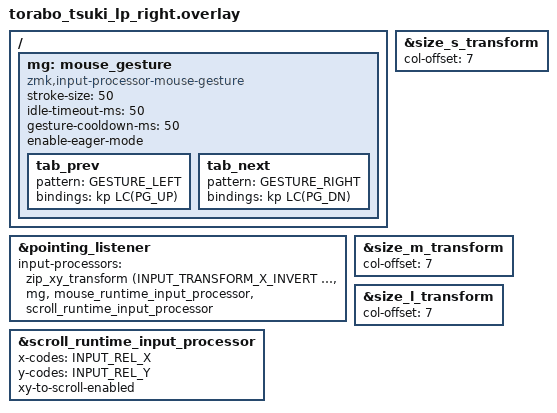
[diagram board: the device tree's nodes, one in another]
#include "torabo_tsuki_lp.dtsi"
#include <input/processors.dtsi>
#include <dt-bindings/zmk/input_transform.h>
#include <input/processors/runtime-input-processor.dtsi>
/* マウスジェスチャー追加 */
#include <dt-bindings/zmk/mouse-gesture.h>

&pointing_listener {
    input-processors = <&zip_xy_transform (INPUT_TRANSFORM_X_INVERT | INPUT_TRANSFORM_Y_INVERT) &mg &mouse_runtime_input_processor &scroll_runtime_input_processor>;
};

&scroll_runtime_input_processor {
        x-codes = <INPUT_REL_X>;
		y-codes = <INPUT_REL_Y>;
		xy-to-scroll-enabled;
};

&size_s_transform {
    col-offset = <7>;
};

&size_m_transform {
    col-offset = <7>;
};

&size_l_transform {
    col-offset = <7>;
};

/ {
    mg: mouse_gesture {
        compatible = "zmk,input-processor-mouse-gesture";
        #input-processor-cells = <0>;
        stroke-size = <50>;
        idle-timeout-ms = <50>;
        gesture-cooldown-ms = <50>;
        enable-eager-mode;

        tab_prev {
            pattern = <GESTURE_LEFT>;
            bindings = <&kp LC(PG_UP)>;
        };

        tab_next {
            pattern = <GESTURE_RIGHT>;
            bindings = <&kp LC(PG_DN)>;
        };
    };
};
